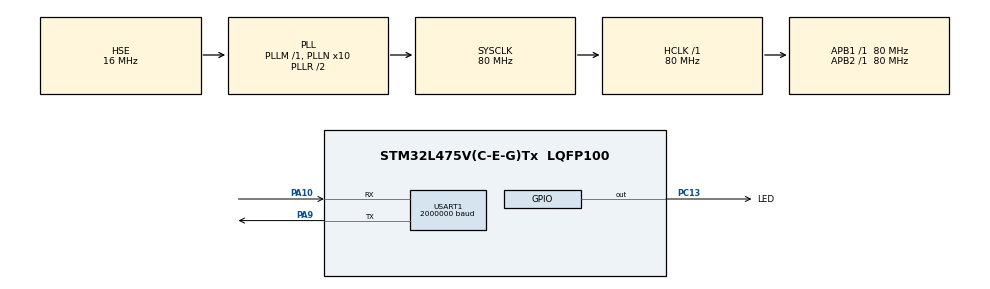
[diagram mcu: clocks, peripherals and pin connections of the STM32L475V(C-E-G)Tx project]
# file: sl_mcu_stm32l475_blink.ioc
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Mcu.Family=STM32L4
Mcu.Name=STM32L475V(C-E-G)Tx
Mcu.Package=LQFP100
NVIC.PriorityGroup=NVIC_PRIORITYGROUP_4
PA10.Mode=Asynchronous
PA10.Signal=USART1_RX
PA13\ (JTMS-SWDIO).Mode=Trace_Asynchronous_SW
PA13\ (JTMS-SWDIO).Signal=SYS_JTMS-SWDIO
PA14\ (JTCK-SWCLK).Mode=Trace_Asynchronous_SW
PA14\ (JTCK-SWCLK).Signal=SYS_JTCK-SWCLK
PA9.Mode=Asynchronous
PA9.Signal=USART1_TX
PB3\ (JTDO-TRACESWO).Mode=Trace_Asynchronous_SW
PB3\ (JTDO-TRACESWO).Signal=SYS_JTDO-SWO
PC13.GPIO_Label=LED
PC13.GPIO_ModeDefaultOutputPP=GPIO_MODE_OUTPUT_OD
PC13.GPIO_PuPd=GPIO_NOPULL
PC13.PinState=GPIO_PIN_SET
PC13.Signal=GPIO_Output
PH0-OSC_IN\ (PH0).Mode=HSE-External-Oscillator
PH0-OSC_IN\ (PH0).Signal=RCC_OSC_IN
PH1-OSC_OUT\ (PH1).Mode=HSE-External-Oscillator
PH1-OSC_OUT\ (PH1).Signal=RCC_OSC_OUT
ProjectManager.HeapSize=0x200
ProjectManager.StackSize=0x400
ProjectManager.TargetToolchain=STM32CubeIDE
RCC.ADCFreq_Value=64000000
RCC.AHBFreq_Value=80000000
RCC.APB1Freq_Value=80000000
RCC.APB1TimFreq_Value=80000000
RCC.APB2Freq_Value=80000000
RCC.APB2TimFreq_Value=80000000
RCC.CortexFreq_Value=80000000
RCC.HCLKFreq_Value=80000000
RCC.HSE_VALUE=16000000
RCC.HSI_VALUE=16000000
RCC.LSE_VALUE=32768
RCC.MSI_VALUE=4000000
RCC.PLLN=10
RCC.PLLSourceVirtual=RCC_PLLSOURCE_HSE
RCC.SYSCLKFreq_VALUE=80000000
RCC.SYSCLKSource=RCC_SYSCLKSOURCE_PLLCLK
RCC.USBFreq_Value=64000000
RCC.VCOOutputFreq_Value=160000000
USART1.BaudRate=2000000
USART1.VirtualMode-Asynchronous=VM_ASYNC
board=custom

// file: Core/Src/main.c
/* USER CODE BEGIN Header */
/**
 ******************************************************************************
 * @file           : main.c
 * @brief          : Main program body
 ******************************************************************************
 * @attention
 *
 * Copyright (c) 2026 STM32World <lth@stm32world.com>
 * All rights reserved.
 *
 * This software is licensed under terms that can be found in the LICENSE file
 * in the root directory of this software component.
 * If no LICENSE file comes with this software, it is provided AS-IS.
 *
 ******************************************************************************
 */
/* USER CODE END Header */
#include "main.h"

UART_HandleTypeDef huart1;

void SystemClock_Config(void);
static void MX_GPIO_Init(void);
static void MX_USART1_UART_Init(void);

int main(void)
{

    /* MCU Configuration--------------------------------------------------------*/

    /* Reset of all peripherals, Initializes the Flash interface and the Systick. */
    HAL_Init();

    /* Configure the system clock */
    SystemClock_Config();

    /* Initialize all configured peripherals */
    MX_GPIO_Init();
    MX_USART1_UART_Init();

    /* Infinite loop */
    /* USER CODE BEGIN WHILE */

    uint32_t now, next_blink = 500;

    while (1) {

        now = uwTick;

        if (now >= next_blink) {
            HAL_GPIO_TogglePin(LED_GPIO_Port, LED_Pin);
            next_blink = now + 500;
        }

        /* USER CODE END WHILE */

    }
}

void SystemClock_Config(void)
{
    RCC_OscInitTypeDef RCC_OscInitStruct = { 0 };
    RCC_ClkInitTypeDef RCC_ClkInitStruct = { 0 };

    /** Configure the main internal regulator output voltage
     */
    if (HAL_PWREx_ControlVoltageScaling(PWR_REGULATOR_VOLTAGE_SCALE1) != HAL_OK)
            {
        Error_Handler();
    }

    /** Initializes the RCC Oscillators according to the specified parameters
     * in the RCC_OscInitTypeDef structure.
     */
    RCC_OscInitStruct.OscillatorType = RCC_OSCILLATORTYPE_HSE;
    RCC_OscInitStruct.HSEState = RCC_HSE_ON;
    RCC_OscInitStruct.PLL.PLLState = RCC_PLL_ON;
    RCC_OscInitStruct.PLL.PLLSource = RCC_PLLSOURCE_HSE;
    RCC_OscInitStruct.PLL.PLLM = 1;
    RCC_OscInitStruct.PLL.PLLN = 10;
    RCC_OscInitStruct.PLL.PLLP = RCC_PLLP_DIV7;
    RCC_OscInitStruct.PLL.PLLQ = RCC_PLLQ_DIV2;
    RCC_OscInitStruct.PLL.PLLR = RCC_PLLR_DIV2;
    if (HAL_RCC_OscConfig(&RCC_OscInitStruct) != HAL_OK)
            {
        Error_Handler();
    }

    /** Initializes the CPU, AHB and APB buses clocks
     */
    RCC_ClkInitStruct.ClockType = RCC_CLOCKTYPE_HCLK | RCC_CLOCKTYPE_SYSCLK
            | RCC_CLOCKTYPE_PCLK1 | RCC_CLOCKTYPE_PCLK2;
    RCC_ClkInitStruct.SYSCLKSource = RCC_SYSCLKSOURCE_PLLCLK;
    RCC_ClkInitStruct.AHBCLKDivider = RCC_SYSCLK_DIV1;
    RCC_ClkInitStruct.APB1CLKDivider = RCC_HCLK_DIV1;
    RCC_ClkInitStruct.APB2CLKDivider = RCC_HCLK_DIV1;

    if (HAL_RCC_ClockConfig(&RCC_ClkInitStruct, FLASH_LATENCY_4) != HAL_OK)
            {
        Error_Handler();
    }
}

static void MX_USART1_UART_Init(void)
{

    huart1.Instance = USART1;
    huart1.Init.BaudRate = 2000000;
    huart1.Init.WordLength = UART_WORDLENGTH_8B;
    huart1.Init.StopBits = UART_STOPBITS_1;
    huart1.Init.Parity = UART_PARITY_NONE;
    huart1.Init.Mode = UART_MODE_TX_RX;
    huart1.Init.HwFlowCtl = UART_HWCONTROL_NONE;
    huart1.Init.OverSampling = UART_OVERSAMPLING_16;
    huart1.Init.OneBitSampling = UART_ONE_BIT_SAMPLE_DISABLE;
    huart1.AdvancedInit.AdvFeatureInit = UART_ADVFEATURE_NO_INIT;
    if (HAL_UART_Init(&huart1) != HAL_OK)
            {
        Error_Handler();
    }

}

static void MX_GPIO_Init(void)
{
    GPIO_InitTypeDef GPIO_InitStruct = { 0 };

    /* GPIO Ports Clock Enable */
    __HAL_RCC_GPIOC_CLK_ENABLE();
    __HAL_RCC_GPIOH_CLK_ENABLE();
    __HAL_RCC_GPIOA_CLK_ENABLE();
    __HAL_RCC_GPIOB_CLK_ENABLE();

    /*Configure GPIO pin Output Level */
    HAL_GPIO_WritePin(LED_GPIO_Port, LED_Pin, GPIO_PIN_SET);

    /*Configure GPIO pin : LED_Pin */
    GPIO_InitStruct.Pin = LED_Pin;
    GPIO_InitStruct.Mode = GPIO_MODE_OUTPUT_OD;
    GPIO_InitStruct.Pull = GPIO_NOPULL;
    GPIO_InitStruct.Speed = GPIO_SPEED_FREQ_LOW;
    HAL_GPIO_Init(LED_GPIO_Port, &GPIO_InitStruct);

}

void Error_Handler(void)
{
    __disable_irq();
    while (1)
    {
    }
}
